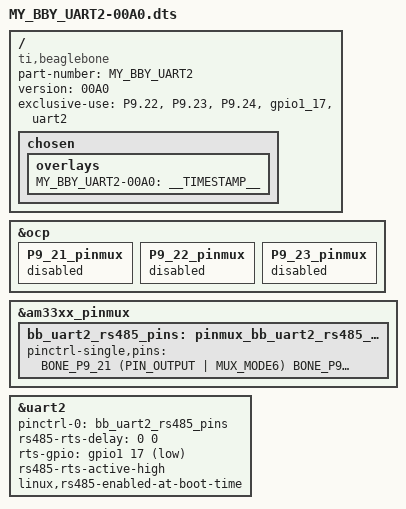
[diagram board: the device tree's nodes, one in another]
/dts-v1/;
/plugin/;

#include <dt-bindings/board/am335x-bbw-bbb-base.h>
#include <dt-bindings/pinctrl/am33xx.h>

/ {
	compatible = "ti,beaglebone", "ti,beaglebone-black", "ti,beaglebone-green";

	// identification
	part-number = "MY_BBY_UART2";
	version = "00A0";

	// resources this cape uses
	exclusive-use =
		"P9.22",		// UART2 TXD
		"P9.23",		// UART2 RXD
		"P9.24",		// UART2 DE
		"gpio1_17",     // UART2 DE
		"uart2";		// hardware ip used

	/*
	 * Helper to show loaded overlays under: /proc/device-tree/chosen/overlays/
	 */
	fragment@0 {
		target-path="/";
		__overlay__ {

			chosen {
				overlays {
					MY_BBY_UART2-00A0 = __TIMESTAMP__;
				};
			};
		};
	};

	/*
	 * Free up the pins used by the cape from the pinmux helpers.
	 */
	fragment@1 {
		target = <&ocp>;
		__overlay__ {
			P9_21_pinmux { status = "disabled"; };	/* P9_21: UART2_TXD */
			P9_22_pinmux { status = "disabled"; };	/* P9_22: UART2_RXD */
			P9_23_pinmux { status = "disabled"; };	/* P9_23: UART2_DE  */
		};
	};

	fragment@2 {
		target = <&am33xx_pinmux>;
		__overlay__ {
			bb_uart2_rs485_pins: pinmux_bb_uart2_rs485_pins {
				pinctrl-single,pins = <
					BONE_P9_21 (PIN_OUTPUT | MUX_MODE6)	/* P9_21: UART2_TXD */
					BONE_P9_22 (PIN_INPUT  | MUX_MODE6)	/* P9_22: UART2_RXD */
					BONE_P9_23 0x07				        /* P9_23: UART2_DE  */
				>;
			};
		};
	};

	fragment@3 {
		target = <&uart2>;
		__overlay__ {
			status = "okay";
			pinctrl-names = "default";
			pinctrl-0 = <&bb_uart2_rs485_pins>;
			rs485-rts-delay = <0 0>;

			rts-gpio = <&gpio1 17 1>; /* P9_23: UART2_DE  */
			rs485-rts-active-high;
			linux,rs485-enabled-at-boot-time;
		};
	};
};




/*
 * Copyright 2015 Sebastian Jegerås
 *
 * This file is dual-licensed: you can use it either under the terms
 * of the GPL or the X11 license, at your option. Note that this dual
 * licensing only applies to this file, and not this project as a
 * whole.
 *
 *  a) This file is free software; you can redistribute it and/or
 *     modify it under the terms of the GNU General Public License as
 *     published by the Free Software Foundation; either version 2 of the
 *     License, or (at your option) any later version.
 *
 *     This file is distributed in the hope that it will be useful,
 *     but WITHOUT ANY WARRANTY; without even the implied warranty of
 *     MERCHANTABILITY or FITNESS FOR A PARTICULAR PURPOSE.  See the
 *     GNU General Public License for more details.
 *
 * Or, alternatively,
 *
 *  b) Permission is hereby granted, free of charge, to any person
 *     obtaining a copy of this software and associated documentation
 *     files (the "Software"), to deal in the Software without
 *     restriction, including without limitation the rights to use,
 *     copy, modify, merge, publish, distribute, sublicense, and/or
 *     sell copies of the Software, and to permit persons to whom the
 *     Software is furnished to do so, subject to the following
 *     conditions:
 *
 *     The above copyright notice and this permission notice shall be
 *     included in all copies or substantial portions of the Software.
 *
 *     THE SOFTWARE IS PROVIDED "AS IS", WITHOUT WARRANTY OF ANY KIND,
 *     EXPRESS OR IMPLIED, INCLUDING BUT NOT LIMITED TO THE WARRANTIES
 *     OF MERCHANTABILITY, FITNESS FOR A PARTICULAR PURPOSE AND
 *     NONINFRINGEMENT. IN NO EVENT SHALL THE AUTHORS OR COPYRIGHT
 *     HOLDERS BE LIABLE FOR ANY CLAIM, DAMAGES OR OTHER LIABILITY,
 *     WHETHER IN AN ACTION OF CONTRACT, TORT OR OTHERWISE, ARISING
 *     FROM, OUT OF OR IN CONNECTION WITH THE SOFTWARE OR THE USE OR
 *     OTHER DEALINGS IN THE SOFTWARE.
 */
